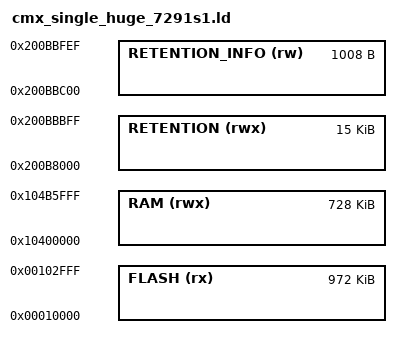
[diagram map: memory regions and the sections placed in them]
MEMORY
{
  FLASH (rx) 	: ORIGIN = 0x00010000, LENGTH = FLASH_SIZE
  RAM (rwx)  	: ORIGIN = 0x10400000, LENGTH = 736K - STACK_SIZE
  RETENTION (rwx)      : ORIGIN = 0x200B8000, LENGTH = 15K
  RETENTION_INFO(rw)   : ORIGIN = 0x200BBC00, LENGTH = 1K - UCODE_HDR_SIZE
}

FLASH_SIZE = 972K;
STACK_SIZE = 8K;
UCODE_HDR_SIZE = 16;
INCLUDE ././lib/modem/cmx_common.ld
